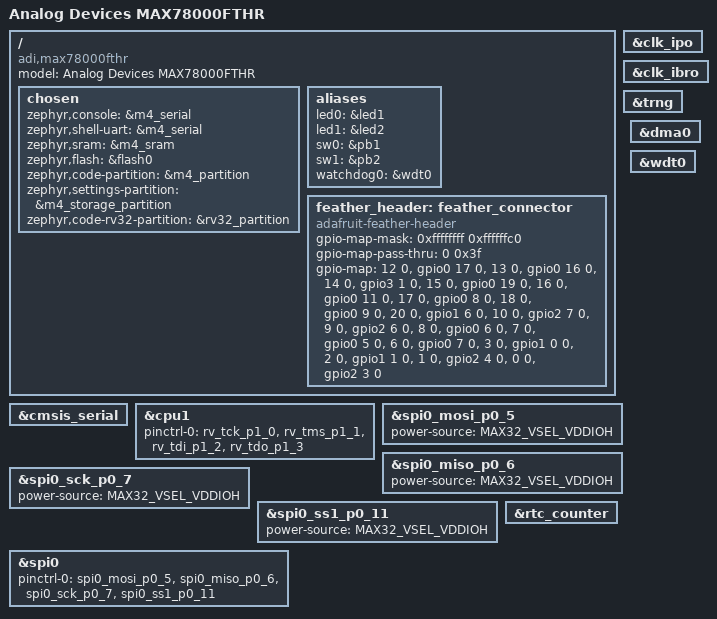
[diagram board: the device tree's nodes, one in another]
/*
 * Copyright (c) 2025 Analog Devices, Inc.
 *
 * SPDX-License-Identifier: Apache-2.0
 */

/dts-v1/;

#include <adi/max32/max78000-m4.dtsi>
#include "max78000fthr.dtsi"

#include <adi/max32/max78000-pinctrl.dtsi>
#include <zephyr/dt-bindings/gpio/adi-max32-gpio.h>
#include <zephyr/dt-bindings/input/input-event-codes.h>

/* Assign the M4 core console to the CMSIS-DAP serial pins */
m4_serial: &cmsis_serial {};

/ {
	model = "Analog Devices MAX78000FTHR";
	compatible = "adi,max78000fthr";

	chosen {
		zephyr,console = &m4_serial;
		zephyr,shell-uart = &m4_serial;
		zephyr,sram = &m4_sram;
		zephyr,flash = &flash0;
		zephyr,code-partition = &m4_partition;
		zephyr,settings-partition = &m4_storage_partition;
		zephyr,code-rv32-partition = &rv32_partition;
	};

	/* These aliases are provided for compatibility with samples */
	aliases {
		led0 = &led1;
		led1 = &led2;
		sw0 = &pb1;
		sw1 = &pb2;
		watchdog0 = &wdt0;
	};

	/* Used for accessing other pins */
	feather_header: feather_connector {
		compatible = "adafruit-feather-header";
		#gpio-cells = <2>;
		gpio-map-mask = <0xffffffff 0xffffffc0>;
		gpio-map-pass-thru = <0 0x3f>;
		gpio-map = <12 0 &gpio0 17 0>,  /* SDA */
			   <13 0 &gpio0 16 0>,  /* SCL */
			   <14 0 &gpio3 1 0>,  /* GPIO */
			   <15 0 &gpio0 19 0>,  /* GPIO */
			   <16 0 &gpio0 11 0>,   /* GPIO */
			   <17 0 &gpio0 8 0>,   /* GPIO */
			   <18 0 &gpio0 9 0>,   /* GPIO */
			   /* 19 connected to the PMIC */   /* GPIO */
			   <20 0 &gpio1 6 0>,   /* GPIO */
			   /* 11 not connected */
			   <10 0 &gpio2 7 0>,  /* TX */
			   <9 0 &gpio2 6 0>,   /* RX */
			   <8 0 &gpio0 6 0>,   /* MISO */
			   <7 0 &gpio0 5 0>,   /* MOSI */
			   <6 0 &gpio0 7 0>,   /* SCK */
			   /* 5 connected to the PMIC */   /* AIN5 */
			   /* 4 connected to the PMIC */   /* AIN4 */
			   <3 0 &gpio1 0 0>,   /* AIN3 */
			   <2 0 &gpio1 1 0>,   /* AIN2 */
			   <1 0 &gpio2 4 0>,   /* AIN1 */
			   <0 0 &gpio2 3 0>;   /* AIN0 */
	};
};

&cpu1 {
	pinctrl-0 = <&rv_tck_p1_0 &rv_tms_p1_1 &rv_tdi_p1_2 &rv_tdo_p1_3>;
	pinctrl-names = "default";
};

&m4_serial {
	status = "okay";
};

&clk_ipo {
	status = "okay";
};

&clk_ibro {
	status = "okay";
};

&trng {
	status = "okay";
};

&spi0_mosi_p0_5 {
	power-source = <MAX32_VSEL_VDDIOH>;
};

&spi0_miso_p0_6 {
	power-source = <MAX32_VSEL_VDDIOH>;
};

&spi0_sck_p0_7 {
	power-source = <MAX32_VSEL_VDDIOH>;
};

&spi0_ss1_p0_11 {
	power-source = <MAX32_VSEL_VDDIOH>;
};

feather_spi: &spi0 {
	status = "okay";
	pinctrl-0 = <&spi0_mosi_p0_5 &spi0_miso_p0_6 &spi0_sck_p0_7 &spi0_ss1_p0_11>;
	pinctrl-names = "default";
};

&dma0 {
	status = "okay";
};

&wdt0 {
	status = "okay";
};

&rtc_counter {
	status = "okay";
};
